AUTOSAR XML (schema 4-2-1)
standard types defined: uint8
package /MyPlateformTypes
  range DATAC_uint8: phys 0..255, raw 0..255
  base type Myuint8: category=FIXED_LENGTH, base-type-size=8, base-type-encoding=NONE, native-declaration=unsigned char
package /Interfaces_Package
  sender receiver interface IF_SR_DoorState
    data DoorState: type=uint8
  client server interface IF_CS_LedSwitch
    operation LED_Switch: possible-error=[E_Not_Ok, E_Ok]
      arg LED_State: type=uint8, direction=IN
    error E_Ok: error-code=0
    error E_Not_Ok: error-code=1
package /SWC_Types_Package
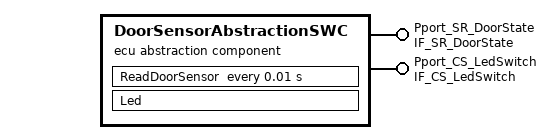
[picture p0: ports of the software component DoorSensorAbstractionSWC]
  ecu abstraction sw component type DoorSensorAbstractionSWC
    provide port Pport_SR_DoorState: provided-interface=IF_SR_DoorState
    provide port Pport_CS_LedSwitch: provided-interface=IF_CS_LedSwitch
    behavior IB_DoorSensorAbstractionSWC
      timing event TE_10ms: start-on-event=ReadDoorSensor, period=0.01
      operation invoked event OIE_LedSwitch: start-on-event=Led, operation=Pport_CS_LedSwitch.LED_Switch
      runnable ReadDoorSensor: symbol=ReadDoorSensor_Runnable
        data-write-access:
          access DA_DoorState: accessed-variable=Pport_SR_DoorState.DoorState
      runnable Led: symbol=LedSwitch_Runnable
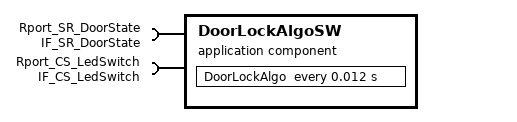
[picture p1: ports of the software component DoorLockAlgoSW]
  application sw component type DoorLockAlgoSW
    require port Rport_SR_DoorState: required-interface=IF_SR_DoorState
    require port Rport_CS_LedSwitch: required-interface=IF_CS_LedSwitch
    behavior IB_DoorLockAlgoSW
      timing event TE_12ms: start-on-event=DoorLockAlgo, period=0.012
      runnable DoorLockAlgo: symbol=DoorLockAlgo_Runnable
        data-read-access:
          access DA_Read_DoorState: accessed-variable=Rport_SR_DoorState.DoorState
        sync call LedSwitch_ServerCall: operation=Rport_CS_LedSwitch.LED_Switch
